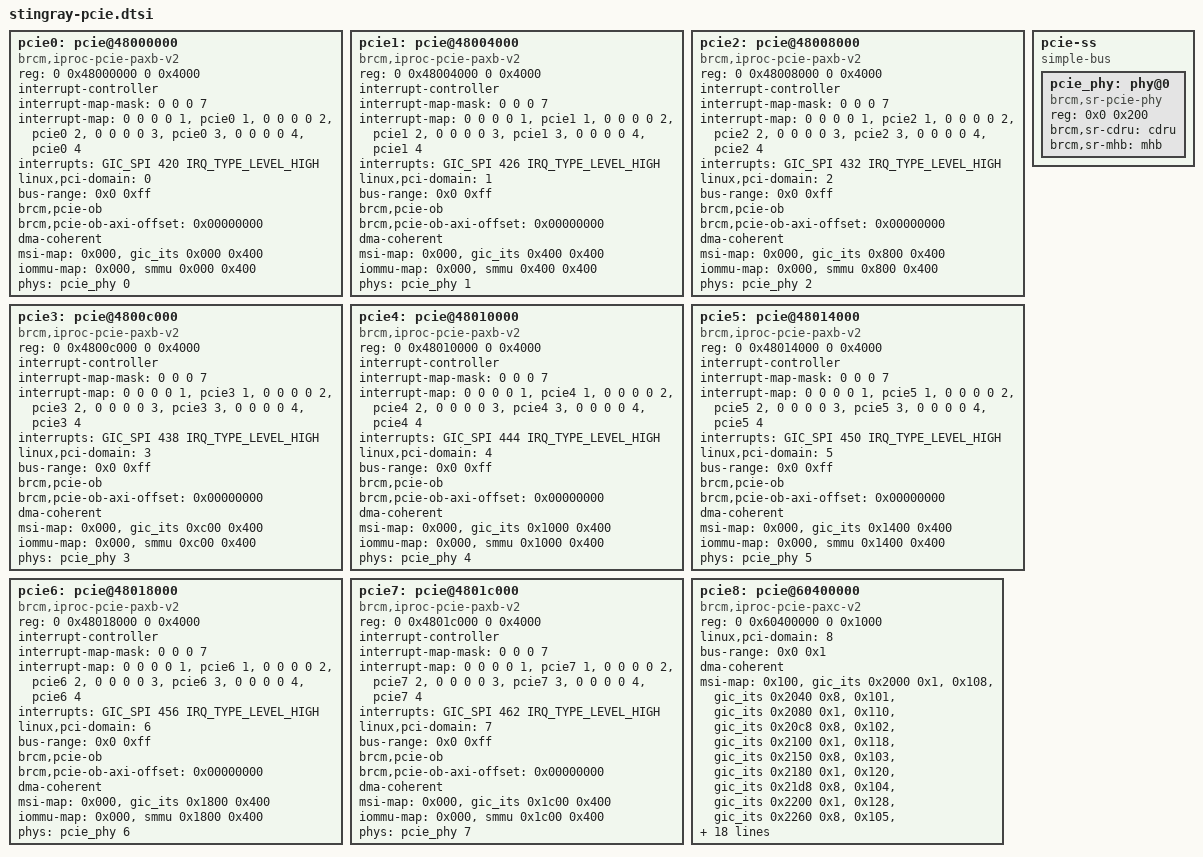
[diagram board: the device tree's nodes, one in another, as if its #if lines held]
// SPDX-License-Identifier: (GPL-2.0 or BSD-3-Clause)
/*
 *Copyright(c) 2018 Broadcom
 */

#if (NUM_PAXB == 8)
#define ENABLE_PCIE0	1
#define ENABLE_PCIE1	1
#define ENABLE_PCIE2	1
#define ENABLE_PCIE3	1
#define ENABLE_PCIE4	1
#define ENABLE_PCIE5	1
#define ENABLE_PCIE6	1
#define ENABLE_PCIE7	1
#endif

#if (NUM_PAXB == 1)
#define ENABLE_PCIE0	1
#endif

	pcie0: pcie@48000000 {
		compatible = "brcm,iproc-pcie-paxb-v2";
		reg = <0 0x48000000 0 0x4000>;

		interrupt-controller;
		#interrupt-cells = <1>;
		interrupt-map-mask = <0 0 0 7>;
		interrupt-map = <0 0 0 0 1 &pcie0 1>,
				<0 0 0 0 2 &pcie0 2>,
				<0 0 0 0 3 &pcie0 3>,
				<0 0 0 0 4 &pcie0 4>;
		interrupts = <GIC_SPI 420 IRQ_TYPE_LEVEL_HIGH>;

		linux,pci-domain = <0>;

		bus-range = <0x0 0xff>;

		#address-cells = <3>;
		#size-cells = <2>;
		device_type = "pci";
#if (ENABLE_32BIT_OUTBOUND == 1)
		ranges = <0x83000000 0x0 0x42000000 0x0 0x42000000 0 0x2000000>,
			 <0x43000000 0x4 0x00000000 0x4 0x00000000 0 0x80000000>;
#else
		ranges = <0x43000000 0x4 0x00000000 0x4 0x00000000 0 0x40000000>,
			 <0x43000000 0x4 0x40000000 0x4 0x40000000 0 0x20000000>,
			 <0x43000000 0x4 0x60000000 0x4 0x60000000 0 0x10000000>,
			 <0x83000000 0x0 0x40000000 0x4 0x70000000 0 0x10000000>;
#endif
		brcm,pcie-ob;
		brcm,pcie-ob-axi-offset = <0x00000000>;

		dma-coherent;

		msi-map = <0x000 &gic_its 0x000 0x400>;

#if (ENABLE_PAXB_IOMMU == 1)
		iommu-map = <0x000 &smmu 0x000 0x400>;
#endif

		phys = <&pcie_phy 0>;
		phy-names = "pcie-phy";

#if (ENABLE_PCIE0 == 1)
		status = "okay";
#else
		status = "disabled";
#endif
	};

	pcie1: pcie@48004000 {
		compatible = "brcm,iproc-pcie-paxb-v2";
		reg = <0 0x48004000 0 0x4000>;

		interrupt-controller;
		#interrupt-cells = <1>;
		interrupt-map-mask = <0 0 0 7>;
		interrupt-map = <0 0 0 0 1 &pcie1 1>,
				<0 0 0 0 2 &pcie1 2>,
				<0 0 0 0 3 &pcie1 3>,
				<0 0 0 0 4 &pcie1 4>;
		interrupts = <GIC_SPI 426 IRQ_TYPE_LEVEL_HIGH>;

		linux,pci-domain = <1>;

		bus-range = <0x0 0xff>;

		#address-cells = <3>;
		#size-cells = <2>;
		device_type = "pci";
#if (ENABLE_32BIT_OUTBOUND == 1)
		ranges = <0x83000000 0x0 0x44000000 0x0 0x44000000 0 0x2000000>,
			 <0x43000000 0x4 0x80000000 0x4 0x80000000 0 0x80000000>;
#else
		ranges = <0x43000000 0x4 0x80000000 0x4 0x80000000 0 0x40000000>,
			 <0x43000000 0x4 0xc0000000 0x4 0xc0000000 0 0x20000000>,
			 <0x43000000 0x4 0xe0000000 0x4 0xe0000000 0 0x10000000>,
			 <0x83000000 0x0 0x40000000 0x4 0xf0000000 0 0x10000000>;
#endif
		brcm,pcie-ob;
		brcm,pcie-ob-axi-offset = <0x00000000>;

		dma-coherent;

		msi-map = <0x000 &gic_its 0x400 0x400>;

#if (ENABLE_PAXB_IOMMU == 1)
		iommu-map = <0x000 &smmu 0x400 0x400>;
#endif

		phys = <&pcie_phy 1>;
		phy-names = "pcie-phy";

#if (ENABLE_PCIE1 == 1)
		status = "okay";
#else
		status = "disabled";
#endif
	};

	pcie2: pcie@48008000 {
		compatible = "brcm,iproc-pcie-paxb-v2";
		reg = <0 0x48008000 0 0x4000>;

		interrupt-controller;
		#interrupt-cells = <1>;
		interrupt-map-mask = <0 0 0 7>;
		interrupt-map = <0 0 0 0 1 &pcie2 1>,
				<0 0 0 0 2 &pcie2 2>,
				<0 0 0 0 3 &pcie2 3>,
				<0 0 0 0 4 &pcie2 4>;
		interrupts = <GIC_SPI 432 IRQ_TYPE_LEVEL_HIGH>;

		linux,pci-domain = <2>;

		bus-range = <0x0 0xff>;

		#address-cells = <3>;
		#size-cells = <2>;
		device_type = "pci";
#if (ENABLE_32BIT_OUTBOUND == 1)
		ranges = <0x83000000 0x0 0x4a000000 0x0 0x4a000000 0 0x2000000>,
			 <0x43000000 0x5 0x00000000 0x5 0x00000000 0 0x80000000>;
#else
		ranges = <0x43000000 0x5 0x00000000 0x5 0x00000000 0 0x40000000>,
			 <0x43000000 0x5 0x40000000 0x5 0x40000000 0 0x20000000>,
			 <0x43000000 0x5 0x60000000 0x5 0x60000000 0 0x10000000>,
			 <0x83000000 0x0 0x40000000 0x5 0x70000000 0 0x10000000>;
#endif
		brcm,pcie-ob;
		brcm,pcie-ob-axi-offset = <0x00000000>;

		dma-coherent;

		msi-map = <0x000 &gic_its 0x800 0x400>;

#if (ENABLE_PAXB_IOMMU == 1)
		iommu-map = <0x000 &smmu 0x800 0x400>;
#endif

		phys = <&pcie_phy 2>;
		phy-names = "pcie-phy";

#if (ENABLE_PCIE2 == 1)
		status = "okay";
#else
		status = "disabled";
#endif
	};

	pcie3: pcie@4800c000 {
		compatible = "brcm,iproc-pcie-paxb-v2";
		reg = <0 0x4800c000 0 0x4000>;

		interrupt-controller;
		#interrupt-cells = <1>;
		interrupt-map-mask = <0 0 0 7>;
		interrupt-map = <0 0 0 0 1 &pcie3 1>,
				<0 0 0 0 2 &pcie3 2>,
				<0 0 0 0 3 &pcie3 3>,
				<0 0 0 0 4 &pcie3 4>;
		interrupts = <GIC_SPI 438 IRQ_TYPE_LEVEL_HIGH>;

		linux,pci-domain = <3>;

		bus-range = <0x0 0xff>;

		#address-cells = <3>;
		#size-cells = <2>;
		device_type = "pci";
#if (ENABLE_32BIT_OUTBOUND == 1)
		ranges = <0x83000000 0x0 0x4c000000 0x0 0x4c000000 0 0x2000000>,
			 <0x43000000 0x5 0x80000000 0x5 0x80000000 0 0x80000000>;
#else
		ranges = <0x43000000 0x5 0x80000000 0x5 0x80000000 0 0x40000000>,
			 <0x43000000 0x5 0xc0000000 0x5 0xc0000000 0 0x20000000>,
			 <0x43000000 0x5 0xe0000000 0x5 0xe0000000 0 0x10000000>,
			 <0x83000000 0x0 0x40000000 0x5 0xf0000000 0 0x10000000>;
#endif
		brcm,pcie-ob;
		brcm,pcie-ob-axi-offset = <0x00000000>;

		dma-coherent;

		msi-map = <0x000 &gic_its 0xc00 0x400>;

#if (ENABLE_PAXB_IOMMU == 1)
		iommu-map = <0x000 &smmu 0xc00 0x400>;
#endif

		phys = <&pcie_phy 3>;
		phy-names = "pcie-phy";

#if (ENABLE_PCIE3 == 1)
		status = "okay";
#else
		status = "disabled";
#endif
	};

	pcie4: pcie@48010000 {
		compatible = "brcm,iproc-pcie-paxb-v2";
		reg = <0 0x48010000 0 0x4000>;

		interrupt-controller;
		#interrupt-cells = <1>;
		interrupt-map-mask = <0 0 0 7>;
		interrupt-map = <0 0 0 0 1 &pcie4 1>,
				<0 0 0 0 2 &pcie4 2>,
				<0 0 0 0 3 &pcie4 3>,
				<0 0 0 0 4 &pcie4 4>;
		interrupts = <GIC_SPI 444 IRQ_TYPE_LEVEL_HIGH>;

		linux,pci-domain = <4>;

		bus-range = <0x0 0xff>;

		#address-cells = <3>;
		#size-cells = <2>;
		device_type = "pci";
#if (ENABLE_32BIT_OUTBOUND == 1)
		ranges = <0x83000000 0x0 0x52000000 0x0 0x52000000 0 0x2000000>,
			 <0x43000000 0x6 0x00000000 0x6 0x00000000 0 0x80000000>;
#else
		ranges = <0x43000000 0x6 0x00000000 0x6 0x00000000 0 0x40000000>,
			 <0x43000000 0x6 0x40000000 0x6 0x40000000 0 0x20000000>,
			 <0x43000000 0x6 0x60000000 0x6 0x60000000 0 0x10000000>,
			 <0x83000000 0x0 0x40000000 0x6 0x70000000 0 0x10000000>;
#endif
		brcm,pcie-ob;
		brcm,pcie-ob-axi-offset = <0x00000000>;

		dma-coherent;

		msi-map = <0x000 &gic_its 0x1000 0x400>;

#if (ENABLE_PAXB_IOMMU == 1)
		iommu-map = <0x000 &smmu 0x1000 0x400>;
#endif

		phys = <&pcie_phy 4>;
		phy-names = "pcie-phy";

#if (ENABLE_PCIE4 == 1)
		status = "okay";
#else
		status = "disabled";
#endif
	};

	pcie5: pcie@48014000 {
		compatible = "brcm,iproc-pcie-paxb-v2";
		reg = <0 0x48014000 0 0x4000>;

		interrupt-controller;
		#interrupt-cells = <1>;
		interrupt-map-mask = <0 0 0 7>;
		interrupt-map = <0 0 0 0 1 &pcie5 1>,
				<0 0 0 0 2 &pcie5 2>,
				<0 0 0 0 3 &pcie5 3>,
				<0 0 0 0 4 &pcie5 4>;
		interrupts = <GIC_SPI 450 IRQ_TYPE_LEVEL_HIGH>;

		linux,pci-domain = <5>;

		bus-range = <0x0 0xff>;

		#address-cells = <3>;
		#size-cells = <2>;
		device_type = "pci";
#if (ENABLE_32BIT_OUTBOUND == 1)
		ranges = <0x83000000 0x0 0x54000000 0x0 0x54000000 0 0x2000000>,
			 <0x43000000 0x6 0x80000000 0x6 0x80000000 0 0x80000000>;
#else
		ranges = <0x43000000 0x6 0x80000000 0x6 0x80000000 0 0x40000000>,
			 <0x43000000 0x6 0xc0000000 0x6 0xc0000000 0 0x20000000>,
			 <0x43000000 0x6 0xe0000000 0x6 0xe0000000 0 0x10000000>,
			 <0x83000000 0x0 0x40000000 0x6 0xf0000000 0 0x10000000>;
#endif
		brcm,pcie-ob;
		brcm,pcie-ob-axi-offset = <0x00000000>;

		dma-coherent;

		msi-map = <0x000 &gic_its 0x1400 0x400>;

#if (ENABLE_PAXB_IOMMU == 1)
		iommu-map = <0x000 &smmu 0x1400 0x400>;
#endif

		phys = <&pcie_phy 5>;
		phy-names = "pcie-phy";

#if (ENABLE_PCIE5 == 1)
		status = "okay";
#else
		status = "disabled";
#endif
	};

	pcie6: pcie@48018000 {
		compatible = "brcm,iproc-pcie-paxb-v2";
		reg = <0 0x48018000 0 0x4000>;

		interrupt-controller;
		#interrupt-cells = <1>;
		interrupt-map-mask = <0 0 0 7>;
		interrupt-map = <0 0 0 0 1 &pcie6 1>,
				<0 0 0 0 2 &pcie6 2>,
				<0 0 0 0 3 &pcie6 3>,
				<0 0 0 0 4 &pcie6 4>;
		interrupts = <GIC_SPI 456 IRQ_TYPE_LEVEL_HIGH>;

		linux,pci-domain = <6>;

		bus-range = <0x0 0xff>;

		#address-cells = <3>;
		#size-cells = <2>;
		device_type = "pci";
#if (ENABLE_32BIT_OUTBOUND == 1)
		ranges = <0x83000000 0x0 0x5a000000 0x0 0x5a000000 0 0x2000000>,
			 <0x43000000 0x7 0x00000000 0x7 0x00000000 0 0x80000000>;
#else
		ranges = <0x43000000 0x7 0x00000000 0x7 0x00000000 0 0x40000000>,
			 <0x43000000 0x7 0x40000000 0x7 0x40000000 0 0x20000000>,
			 <0x43000000 0x7 0x60000000 0x7 0x60000000 0 0x10000000>,
			 <0x83000000 0x0 0x40000000 0x7 0x70000000 0 0x10000000>;
#endif
		brcm,pcie-ob;
		brcm,pcie-ob-axi-offset = <0x00000000>;

		dma-coherent;

		msi-map = <0x000 &gic_its 0x1800 0x400>;

#if (ENABLE_PAXB_IOMMU == 1)
		iommu-map = <0x000 &smmu 0x1800 0x400>;
#endif

		phys = <&pcie_phy 6>;
		phy-names = "pcie-phy";

#if (ENABLE_PCIE6 == 1)
		status = "okay";
#else
		status = "disabled";
#endif
	};

	pcie7: pcie@4801c000 {
		compatible = "brcm,iproc-pcie-paxb-v2";
		reg = <0 0x4801c000 0 0x4000>;

		interrupt-controller;
		#interrupt-cells = <1>;
		interrupt-map-mask = <0 0 0 7>;
		interrupt-map = <0 0 0 0 1 &pcie7 1>,
				<0 0 0 0 2 &pcie7 2>,
				<0 0 0 0 3 &pcie7 3>,
				<0 0 0 0 4 &pcie7 4>;
		interrupts = <GIC_SPI 462 IRQ_TYPE_LEVEL_HIGH>;

		linux,pci-domain = <7>;

		bus-range = <0x0 0xff>;

		#address-cells = <3>;
		#size-cells = <2>;
		device_type = "pci";
#if (ENABLE_32BIT_OUTBOUND == 1)
		ranges = <0x83000000 0x0 0x5c000000 0x0 0x5c000000 0 0x2000000>,
			 <0x43000000 0x7 0x80000000 0x7 0x80000000 0 0x80000000>;
#else
		ranges = <0x43000000 0x7 0x80000000 0x7 0x80000000 0 0x40000000>,
			 <0x43000000 0x7 0xc0000000 0x7 0xc0000000 0 0x20000000>,
			 <0x43000000 0x7 0xd0000000 0x7 0xe0000000 0 0x10000000>,
			 <0x83000000 0x0 0x40000000 0x7 0xf0000000 0 0x10000000>;
#endif
		brcm,pcie-ob;
		brcm,pcie-ob-axi-offset = <0x00000000>;

		dma-coherent;

		msi-map = <0x000 &gic_its 0x1c00 0x400>;

#if (ENABLE_PAXB_IOMMU == 1)
		iommu-map = <0x000 &smmu 0x1c00 0x400>;
#endif

		phys = <&pcie_phy 7>;
		phy-names = "pcie-phy";

#if (ENABLE_PCIE7 == 1)
		status = "okay";
#else
		status = "disabled";
#endif
	};

	pcie8: pcie@60400000 {
		compatible = "brcm,iproc-pcie-paxc-v2";
		reg = <0 0x60400000 0 0x1000>;
		linux,pci-domain = <8>;

		bus-range = <0x0 0x1>;

		#address-cells = <3>;
		#size-cells = <2>;
		device_type = "pci";
		ranges = <0x83000000 0 0x10000000 0 0x10000000 0 0x20000000>;

		dma-coherent;

		msi-map = <0x100 &gic_its 0x2000 0x1>, /* PF0 */
			  <0x108 &gic_its 0x2040 0x8>, /* PF0-VF0-7 */
			  <0x101 &gic_its 0x2080 0x1>, /* PF1 */
			  <0x110 &gic_its 0x20c8 0x8>, /* PF1-VF8-15 */
			  <0x102 &gic_its 0x2100 0x1>, /* PF2 */
			  <0x118 &gic_its 0x2150 0x8>, /* PF2-VF16-23 */
			  <0x103 &gic_its 0x2180 0x1>, /* PF3 */
			  <0x120 &gic_its 0x21d8 0x8>, /* PF3-VF24-31 */
			  <0x104 &gic_its 0x2200 0x1>, /* PF4 */
			  <0x128 &gic_its 0x2260 0x8>, /* PF4-VF32-39 */
			  <0x105 &gic_its 0x2280 0x1>, /* PF5 */
			  <0x130 &gic_its 0x22e8 0x8>, /* PF5-VF40-47 */
			  <0x106 &gic_its 0x2300 0x1>, /* PF6 */
			  <0x138 &gic_its 0x2370 0x8>, /* PF6-VF48-55 */
			  <0x107 &gic_its 0x2380 0x1>, /* PF7 */
			  <0x140 &gic_its 0x23f8 0x8>; /* PF7-VF56-63 */

#if (ENABLE_PAXC_IOMMU == 1)
		iommu-map = <0x100 &smmu 0x2000 0x1>, /* PF0 */
			    <0x108 &smmu 0x2040 0x8>, /* PF0-VF0-7 */
			    <0x101 &smmu 0x2080 0x1>, /* PF1 */
			    <0x110 &smmu 0x20c8 0x8>, /* PF1-VF8-15 */
			    <0x102 &smmu 0x2100 0x1>, /* PF2 */
			    <0x118 &smmu 0x2150 0x8>, /* PF2-VF16-23 */
			    <0x103 &smmu 0x2180 0x1>, /* PF3 */
			    <0x120 &smmu 0x21d8 0x8>, /* PF3-VF24-31 */
			    <0x104 &smmu 0x2200 0x1>, /* PF4 */
			    <0x128 &smmu 0x2260 0x8>, /* PF4-VF32-39 */
			    <0x105 &smmu 0x2280 0x1>, /* PF5 */
			    <0x130 &smmu 0x22e8 0x8>, /* PF5-VF40-47 */
			    <0x106 &smmu 0x2300 0x1>, /* PF6 */
			    <0x138 &smmu 0x2370 0x8>, /* PF6-VF48-55 */
			    <0x107 &smmu 0x2380 0x1>, /* PF7 */
			    <0x140 &smmu 0x23f8 0x8>; /* PF7-VF56-63 */
#endif

		phys = <&pcie_phy 8>;
		phy-names = "pcie-phy";

#if (ENABLE_PAXC == 1)
		status = "okay";
#else
		status = "disabled";
#endif
	};

pcie-ss {
	compatible = "simple-bus";
	#address-cells = <1>;
	#size-cells = <1>;
	ranges = <0x0 0x0 0x40000000 0x800>;

	pcie_phy: phy@0 {
		compatible = "brcm,sr-pcie-phy";
		reg = <0x0 0x200>;
		brcm,sr-cdru = <&cdru>;
		brcm,sr-mhb = <&mhb>;
		#phy-cells = <1>;
	};
};
